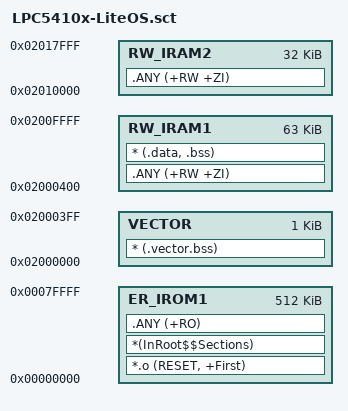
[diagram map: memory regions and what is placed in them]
; *************************************************************
; *** Scatter-Loading Description File generated by uVision ***
; *************************************************************

LR_IROM1 0x00000000 0x80000  {    ; load region size_region
  ER_IROM1 0x00000000 0x80000  {  ; load address = execution address
   *.o (RESET, +First)
   *(InRoot$$Sections)
   .ANY (+RO)
  }
  VECTOR 0x02000000 0x400 { ;vector 1kB
   * (.vector.bss)
  }

  RW_IRAM1 0x02000400 0xFC00  {  ; RW data 63kB
   .ANY (+RW +ZI)
   * (.data, .bss)
  }
  RW_IRAM2 0x02010000 0x8000  {  ; RW data 32kB, enable by PCON before use
   .ANY (+RW +ZI)
  }
}

